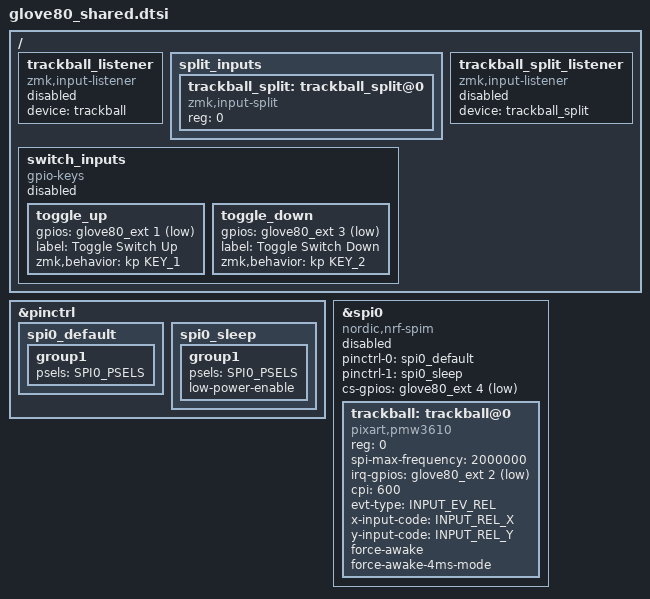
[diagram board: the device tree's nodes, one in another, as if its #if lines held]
#define SPI_PSELS(sck_port, sck_pin, sdio_port, sdio_pin) \
    <NRF_PSEL(SPIM_SCK, sck_port, sck_pin)>, \
    <NRF_PSEL(SPIM_MOSI, sdio_port, sdio_pin)>, \
    <NRF_PSEL(SPIM_MISO, sdio_port, sdio_pin)>

#ifdef CONFIG_BOARD_GLOVE80_RH
    #define SPI0_PSELS SPI_PSELS(1, 0, 0, 22)
    /* SCLK = EXT6 = P1.00 */
    /* SDIO = EXT5 = P0.22 */
#elif defined(CONFIG_BOARD_GLOVE80_LH)
    #define SPI0_PSELS SPI_PSELS(1, 0, 0, 25)
    /* SCLK = EXT6 = P1.00 */
    /* SDIO = EXT5 = P0.25 */
#endif

&pinctrl {
    spi0_default: spi0_default {
        group1 {
            psels = SPI0_PSELS;
        };
    };

    spi0_sleep: spi0_sleep {
        group1 {
            psels = SPI0_PSELS;
            low-power-enable;
        };
    };
};


&spi0 {
    status = "disabled";
    compatible = "nordic,nrf-spim";
    pinctrl-0 = <&spi0_default>;
    pinctrl-1 = <&spi0_sleep>;
    pinctrl-names = "default", "sleep";
    cs-gpios = <&glove80_ext 4 GPIO_ACTIVE_LOW>; /* nCS = EXT4 = P0.25 */
    /*cs-gpios = <&gpio0 25 GPIO_ACTIVE_LOW>;*/

    trackball: trackball@0 {
        status = "okay";
        compatible = "pixart,pmw3610";
        reg = <0>;
        spi-max-frequency = <2000000>;
        irq-gpios = <&glove80_ext 2 (GPIO_ACTIVE_LOW | GPIO_PULL_UP)>; /* Mot = EXT2 = P0.24 */
        /*irq-gpios = <&gpio0 24 (GPIO_ACTIVE_LOW | GPIO_PULL_UP)>;*/
        cpi = <600>;
        evt-type = <INPUT_EV_REL>;
        x-input-code = <INPUT_REL_X>;
        y-input-code = <INPUT_REL_Y>;

        force-awake;
        /* keep the sensor awake while ZMK activity state is ACTIVE,
           fallback to normal downshift mode after ZMK goes into IDLE / SLEEP mode.
           thus, the sensor would be a `wakeup-source` */

#ifdef CONFIG_ZMK_USB
        force-awake-4ms-mode;
#endif
        /* while force-awake is acitvated, enable this mode to force sampling per 
           4ms, where the default sampling rate is 8ms. */
        /* NOTE: apply this mode if you need 250Hz with direct USB connection. */
    };
};

/ {
    // regular listener if trackball is used on split central
    trackball_listener: trackball_listener {
        compatible = "zmk,input-listener";
        status = "disabled";
        device = <&trackball>;
    };

    split_inputs {
        #address-cells = <1>;
        #size-cells = <0>;

        trackball_split: trackball_split@0 {
            compatible = "zmk,input-split";
            reg = <0>;
        };
    };

    // split listener if trackball is used on split peripheral over BLE
    trackball_split_listener: trackball_split_listener {
        compatible = "zmk,input-listener";
        status = "disabled";
        device = <&trackball_split>;
    };
    
    switch_inputs: switch_inputs {
        compatible = "gpio-keys";
        status = "disabled";

        toggle_up {
            gpios = <&glove80_ext 1 GPIO_ACTIVE_LOW>;
            label = "Toggle Switch Up";
            zmk,behavior = <&kp KEY_1>;
        };

        toggle_down {
            gpios = <&glove80_ext 3 GPIO_ACTIVE_LOW>;
            label = "Toggle Switch Down";
            zmk,behavior = <&kp KEY_2>;
        };
    };
};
